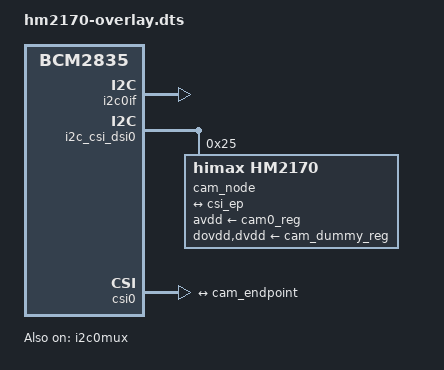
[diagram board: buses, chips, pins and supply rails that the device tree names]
/dts-v1/;
/plugin/;

/*
 * HM2170 on Raspberry Pi 5 CAM/DISP 0.
 * 2 lanes. 27 MHz module crystal. Link 540 MHz is the Intel 384 MHz
 * table scaled from 19.2 MHz onto 27 MHz. This module answers at I2C 0x25.
 */

/{
	compatible = "brcm,bcm2835";

	fragment@0 {
		target = <&i2c0if>;
		__overlay__ {
			status = "okay";
		};
	};

	fragment@1 {
		target = <&i2c0mux>;
		__overlay__ {
			status = "okay";
		};
	};

	fragment@2 {
		target = <&cam0_clk>;
		__overlay__ {
			status = "okay";
			clock-frequency = <27000000>;
		};
	};

	fragment@3 {
		target = <&i2c_csi_dsi0>;
		__overlay__ {
			#address-cells = <1>;
			#size-cells = <0>;
			status = "okay";

			cam_node: hm2170@25 {
				compatible = "himax,hm2170";
				reg = <0x25>;
				status = "okay";

				clocks = <&cam0_clk>;
				clock-names = "xclk";

				avdd-supply = <&cam0_reg>;
				dovdd-supply = <&cam_dummy_reg>;
				dvdd-supply = <&cam_dummy_reg>;

				rotation = <0>;
				orientation = <2>;

				port {
					cam_endpoint: endpoint {
						clock-lanes = <0>;
						data-lanes = <1 2>;
						link-frequencies =
							/bits/ 64 <540000000>;
						remote-endpoint = <&csi_ep>;
					};
				};
			};
		};
	};

	fragment@4 {
		target = <&csi0>;
		__overlay__ {
			status = "okay";

			port {
				csi_ep: endpoint {
					remote-endpoint = <&cam_endpoint>;
					clock-lanes = <0>;
					data-lanes = <1 2>;
				};
			};
		};
	};
};
